AUTOSAR XML (schema 314)
package /ComponentType
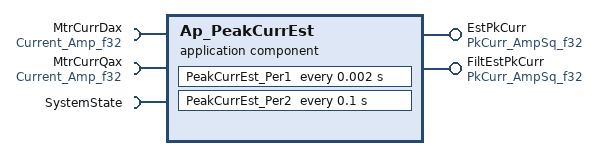
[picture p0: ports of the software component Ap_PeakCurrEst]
  application software component type Ap_PeakCurrEst
    provide port EstPkCurr: unqueued-sender-com-spec{data-element=AmpSq_f32, can-invalidate=false, init-value=D_ZERO_ULS_F32}, provided-interface=PkCurr_AmpSq_f32
    provide port FiltEstPkCurr: unqueued-sender-com-spec{data-element=AmpSq_f32, can-invalidate=false, init-value=D_ZERO_ULS_F32}, provided-interface=PkCurr_AmpSq_f32
    require port MtrCurrDax: unqueued-receiver-com-spec{data-element=Amp_f32, init-value=D_ZERO_ULS_F32}, required-interface=Current_Amp_f32
    require port MtrCurrQax: unqueued-receiver-com-spec{data-element=Amp_f32, init-value=D_ZERO_ULS_F32}, required-interface=Current_Amp_f32
    require port SystemState: required-interface=SystemState
  internal behavior Ap_PeakCurrEst_InternalBehavior: component=Ap_PeakCurrEst
    timing event TMT_PeakCurrEst_Per1: mode-dependency=dependent-on-mode=SystemState.Mode.WARMINIT, start-on-event=PeakCurrEst_Per1, period=0.002
    timing event TMT_PeakCurrEst_Per2: mode-dependency=dependent-on-mode=SystemState.Mode.WARMINIT, start-on-event=PeakCurrEst_Per2, period=0.1
    port-api-options:
      enable-take-address=false, indirect-api=false, port=EstPkCurr
      enable-take-address=false, indirect-api=false, port=FiltEstPkCurr
      enable-take-address=false, indirect-api=false, port=MtrCurrDax
      enable-take-address=false, indirect-api=false, port=MtrCurrQax
      enable-take-address=false, indirect-api=false, port=SystemState
    runnable PeakCurrEst_Per1
      data read access READ_MtrCurrDax_Amp_f32: data-element=MtrCurrDax.Amp_f32
      data read access READ_MtrCurrQax_Amp_f32: data-element=MtrCurrQax.Amp_f32
      data write access WRITE_EstPkCurr_AmpSq_f32: data-element=EstPkCurr.AmpSq_f32
    runnable PeakCurrEst_Per2
      data write access WRITE_FiltEstPkCurr_AmpSq_f32: data-element=FiltEstPkCurr.AmpSq_f32
  swc implementation Ap_PeakCurrEst_Implementation: behavior=Ap_PeakCurrEst_InternalBehavior
    code-descriptors:
      code Code: type=SRC
